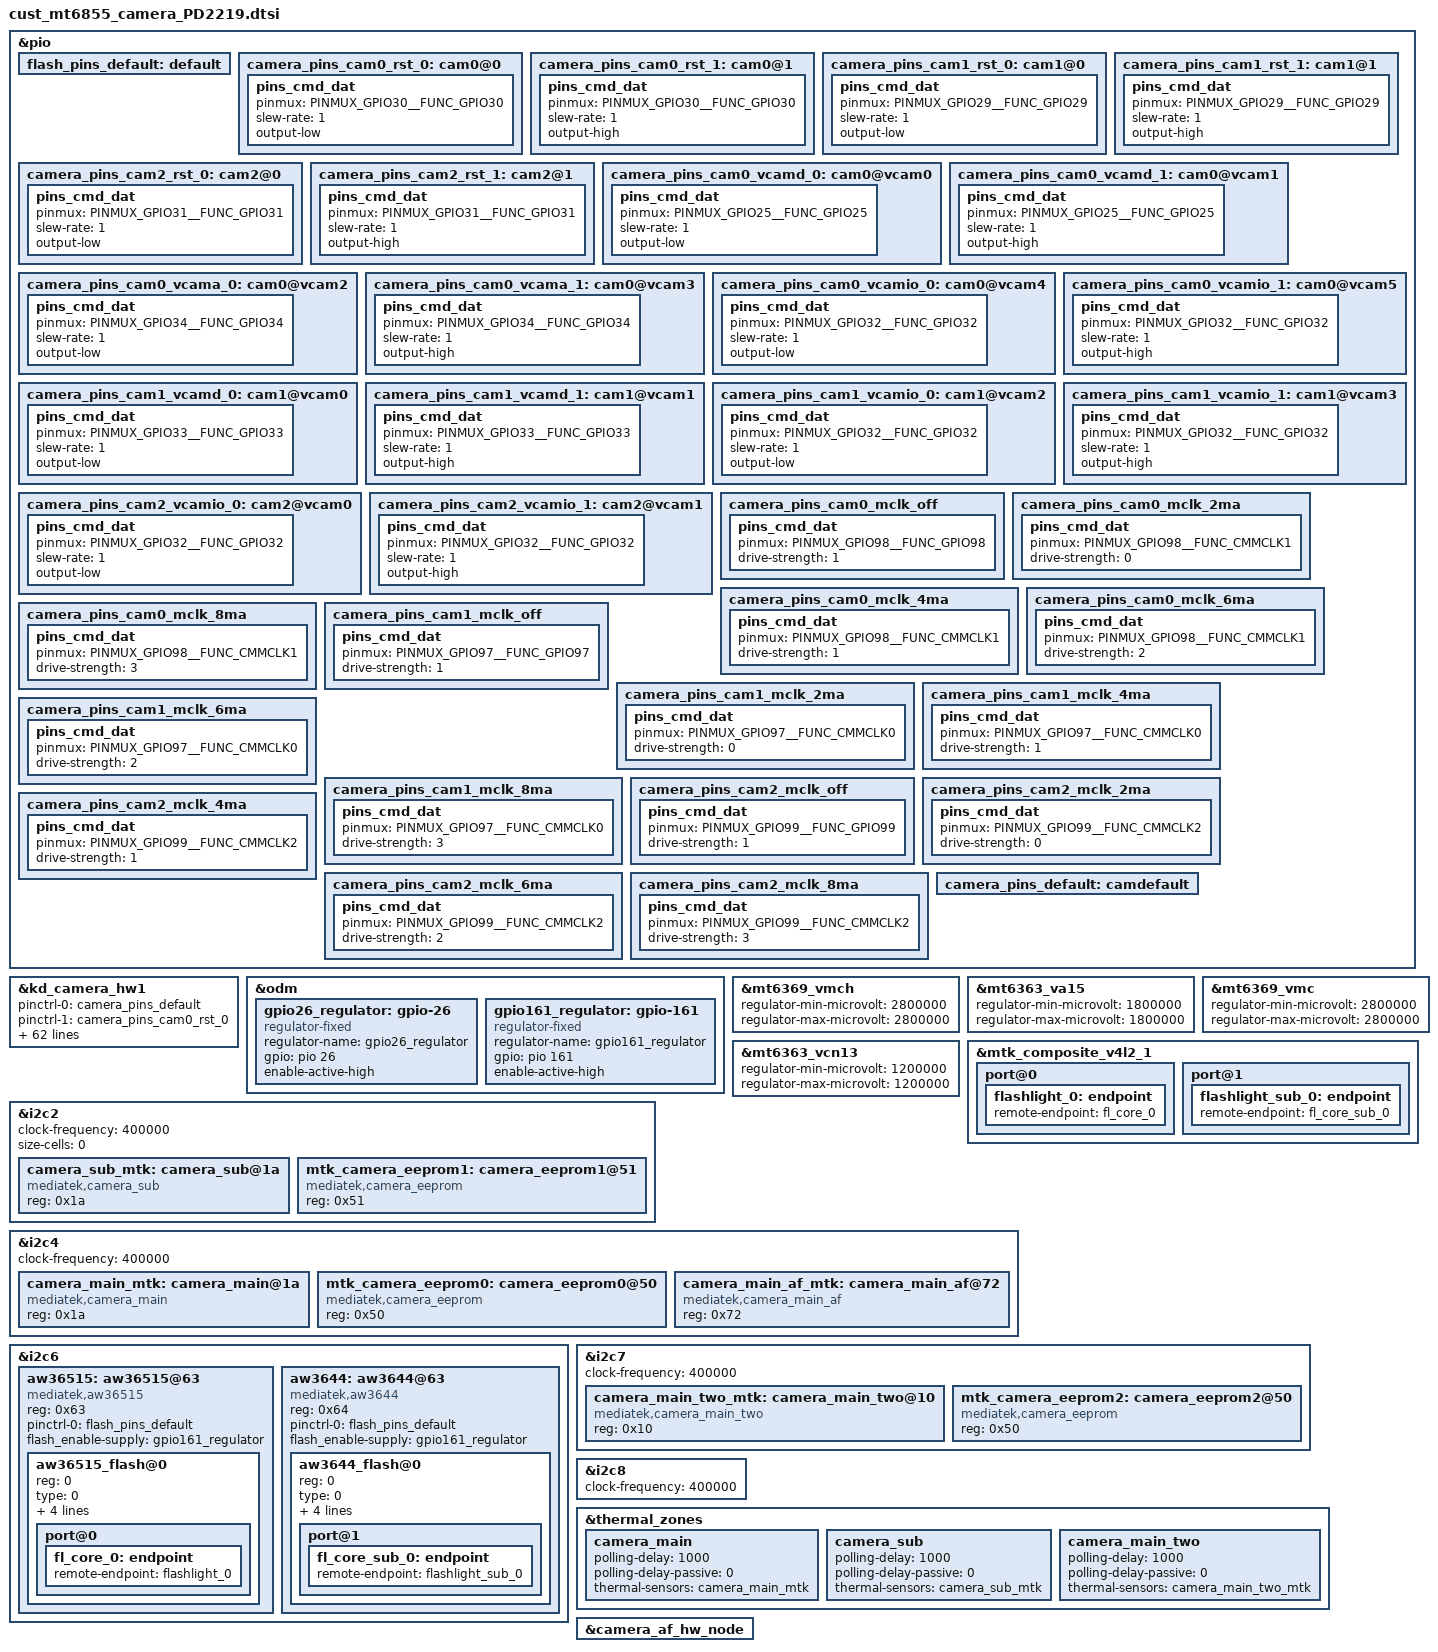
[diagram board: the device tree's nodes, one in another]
// SPDX-License-Identifier: GPL-2.0
/* Copyright (c) 2020 MediaTek Inc. */
/* CAMERA GPIO standardization */

/* flash led */
&pio {
	flash_pins_default: default {
	};
};
&pio {
	camera_pins_cam0_rst_0: cam0@0 {
		pins_cmd_dat {
			pinmux = <PINMUX_GPIO30__FUNC_GPIO30>;
			slew-rate = <1>;
			output-low;
		};
	};
	camera_pins_cam0_rst_1: cam0@1 {
		pins_cmd_dat {
			pinmux = <PINMUX_GPIO30__FUNC_GPIO30>;
			slew-rate = <1>;
			output-high;
		};
	};

	camera_pins_cam1_rst_0: cam1@0 {
		pins_cmd_dat {
			pinmux = <PINMUX_GPIO29__FUNC_GPIO29>;
			slew-rate = <1>;
			output-low;
		};
	};
	camera_pins_cam1_rst_1: cam1@1 {
		pins_cmd_dat {
			pinmux = <PINMUX_GPIO29__FUNC_GPIO29>;
			slew-rate = <1>;
			output-high;
		};
	};

	camera_pins_cam2_rst_0: cam2@0 {
		pins_cmd_dat {
			pinmux = <PINMUX_GPIO31__FUNC_GPIO31>;
			slew-rate = <1>;
			output-low;
		};
	};
	camera_pins_cam2_rst_1: cam2@1 {
		pins_cmd_dat {
			pinmux = <PINMUX_GPIO31__FUNC_GPIO31>;
			slew-rate = <1>;
			output-high;
		};
	};

	camera_pins_cam0_vcamd_0: cam0@vcam0 {
		pins_cmd_dat {
			pinmux = <PINMUX_GPIO25__FUNC_GPIO25>;
			slew-rate = <1>;
			output-low;
		};
	};
	camera_pins_cam0_vcamd_1: cam0@vcam1 {
		pins_cmd_dat {
			pinmux = <PINMUX_GPIO25__FUNC_GPIO25>;
			slew-rate = <1>;
			output-high;
		};
	};
	camera_pins_cam0_vcama_0: cam0@vcam2 {
		pins_cmd_dat {
			pinmux = <PINMUX_GPIO34__FUNC_GPIO34>;
			slew-rate = <1>;
			output-low;
		};
	};
	camera_pins_cam0_vcama_1: cam0@vcam3 {
		pins_cmd_dat {
			pinmux = <PINMUX_GPIO34__FUNC_GPIO34>;
			slew-rate = <1>;
			output-high;
		};
	};
	camera_pins_cam0_vcamio_0: cam0@vcam4 {
		pins_cmd_dat {
			pinmux = <PINMUX_GPIO32__FUNC_GPIO32>;
			slew-rate = <1>;
			output-low;
		};
	};
	camera_pins_cam0_vcamio_1: cam0@vcam5 {
		pins_cmd_dat {
			pinmux = <PINMUX_GPIO32__FUNC_GPIO32>;
			slew-rate = <1>;
			output-high;
		};
	};
	camera_pins_cam1_vcamd_0: cam1@vcam0 {
		pins_cmd_dat {
			pinmux = <PINMUX_GPIO33__FUNC_GPIO33>;
			slew-rate = <1>;
			output-low;
		};
	};
	camera_pins_cam1_vcamd_1: cam1@vcam1 {
		pins_cmd_dat {
			pinmux = <PINMUX_GPIO33__FUNC_GPIO33>;
			slew-rate = <1>;
			output-high;
		};
	};
	camera_pins_cam1_vcamio_0: cam1@vcam2 {
		pins_cmd_dat {
			pinmux = <PINMUX_GPIO32__FUNC_GPIO32>;
			slew-rate = <1>;
			output-low;
		};
	};
	camera_pins_cam1_vcamio_1: cam1@vcam3 {
		pins_cmd_dat {
			pinmux = <PINMUX_GPIO32__FUNC_GPIO32>;
			slew-rate = <1>;
			output-high;
		};
	};
	camera_pins_cam2_vcamio_0: cam2@vcam0 {
		pins_cmd_dat {
			pinmux = <PINMUX_GPIO32__FUNC_GPIO32>;
			slew-rate = <1>;
			output-low;
		};
	};
	camera_pins_cam2_vcamio_1: cam2@vcam1 {
		pins_cmd_dat {
			pinmux = <PINMUX_GPIO32__FUNC_GPIO32>;
			slew-rate = <1>;
			output-high;
		};
	};
	camera_pins_cam0_mclk_off: camera_pins_cam0_mclk_off {
		pins_cmd_dat {
			pinmux = <PINMUX_GPIO98__FUNC_GPIO98>;
			drive-strength = <1>;
		};
	};
	camera_pins_cam0_mclk_2ma: camera_pins_cam0_mclk_2ma {
		pins_cmd_dat {
			pinmux = <PINMUX_GPIO98__FUNC_CMMCLK1>;
			drive-strength = <0>;
		};
	};
	camera_pins_cam0_mclk_4ma: camera_pins_cam0_mclk_4ma {
		pins_cmd_dat {
			pinmux = <PINMUX_GPIO98__FUNC_CMMCLK1>;
			drive-strength = <1>;
		};
	};
	camera_pins_cam0_mclk_6ma: camera_pins_cam0_mclk_6ma {
		pins_cmd_dat {
			pinmux = <PINMUX_GPIO98__FUNC_CMMCLK1>;
			drive-strength = <2>;
		};
	};
	camera_pins_cam0_mclk_8ma: camera_pins_cam0_mclk_8ma {
		pins_cmd_dat {
			pinmux = <PINMUX_GPIO98__FUNC_CMMCLK1>;
			drive-strength = <3>;
		};
	};
	camera_pins_cam1_mclk_off: camera_pins_cam1_mclk_off {
		pins_cmd_dat {
			pinmux = <PINMUX_GPIO97__FUNC_GPIO97>;
			drive-strength = <1>;
		};
	};
	camera_pins_cam1_mclk_2ma: camera_pins_cam1_mclk_2ma {
		pins_cmd_dat {
			pinmux = <PINMUX_GPIO97__FUNC_CMMCLK0>;
			drive-strength = <0>;
		};
	};
	camera_pins_cam1_mclk_4ma: camera_pins_cam1_mclk_4ma {
		pins_cmd_dat {
			pinmux = <PINMUX_GPIO97__FUNC_CMMCLK0>;
			drive-strength = <1>;
		};
	};
	camera_pins_cam1_mclk_6ma: camera_pins_cam1_mclk_6ma {
		pins_cmd_dat {
			pinmux = <PINMUX_GPIO97__FUNC_CMMCLK0>;
			drive-strength = <2>;
		};
	};
	camera_pins_cam1_mclk_8ma: camera_pins_cam1_mclk_8ma {
		pins_cmd_dat {
			pinmux = <PINMUX_GPIO97__FUNC_CMMCLK0>;
			drive-strength = <3>;
		};
	};
	camera_pins_cam2_mclk_off: camera_pins_cam2_mclk_off {
		pins_cmd_dat {
			pinmux = <PINMUX_GPIO99__FUNC_GPIO99>;
			drive-strength = <1>;
		};
	};
	camera_pins_cam2_mclk_2ma: camera_pins_cam2_mclk_2ma {
		pins_cmd_dat {
			pinmux = <PINMUX_GPIO99__FUNC_CMMCLK2>;
			drive-strength = <0>;
		};
	};
	camera_pins_cam2_mclk_4ma: camera_pins_cam2_mclk_4ma {
		pins_cmd_dat {
			pinmux = <PINMUX_GPIO99__FUNC_CMMCLK2>;
			drive-strength = <1>;
		};
	};
	camera_pins_cam2_mclk_6ma: camera_pins_cam2_mclk_6ma {
		pins_cmd_dat {
			pinmux = <PINMUX_GPIO99__FUNC_CMMCLK2>;
			drive-strength = <2>;
		};
	};
	camera_pins_cam2_mclk_8ma: camera_pins_cam2_mclk_8ma {
		pins_cmd_dat {
			pinmux = <PINMUX_GPIO99__FUNC_CMMCLK2>;
			drive-strength = <3>;
		};
	};
	camera_pins_default: camdefault {
	};
};
&kd_camera_hw1 {
	pinctrl-names = "default",
			"cam0_rst0", "cam0_rst1",
			"cam1_rst0", "cam1_rst1",
			"cam2_rst0", "cam2_rst1",
			"cam0_ldo_vcamd_0", "cam0_ldo_vcamd_1",
			"cam0_ldo_vcama_0", "cam0_ldo_vcama_1",
			"cam0_ldo_vcamio_0", "cam0_ldo_vcamio_1",
			"cam1_ldo_vcamd_0", "cam1_ldo_vcamd_1",
			"cam1_ldo_vcamio_0", "cam1_ldo_vcamio_1",
			"cam2_ldo_vcamio_0", "cam2_ldo_vcamio_1",
			"cam0_mclk_off",
			"cam0_mclk_2mA", "cam0_mclk_4mA",
			"cam0_mclk_6mA", "cam0_mclk_8mA",
			"cam1_mclk_off",
			"cam1_mclk_2mA", "cam1_mclk_4mA",
			"cam1_mclk_6mA", "cam1_mclk_8mA",
			"cam2_mclk_off",
			"cam2_mclk_2mA", "cam2_mclk_4mA",
			"cam2_mclk_6mA", "cam2_mclk_8mA";
	pinctrl-0 = <&camera_pins_default>;
	pinctrl-1 = <&camera_pins_cam0_rst_0>;
	pinctrl-2 = <&camera_pins_cam0_rst_1>;
	pinctrl-3 = <&camera_pins_cam1_rst_0>;
	pinctrl-4 = <&camera_pins_cam1_rst_1>;
	pinctrl-5 = <&camera_pins_cam2_rst_0>;
	pinctrl-6 = <&camera_pins_cam2_rst_1>;
	pinctrl-7 = <&camera_pins_cam0_vcamd_0>;
	pinctrl-8 = <&camera_pins_cam0_vcamd_1>;
	pinctrl-9 = <&camera_pins_cam0_vcama_0>;
	pinctrl-10 = <&camera_pins_cam0_vcama_1>;
	pinctrl-11 = <&camera_pins_cam0_vcamio_0>;
	pinctrl-12 = <&camera_pins_cam0_vcamio_1>;
	pinctrl-13 = <&camera_pins_cam1_vcamd_0>;
	pinctrl-14 = <&camera_pins_cam1_vcamd_1>;
	pinctrl-15 = <&camera_pins_cam1_vcamio_0>;
	pinctrl-16 = <&camera_pins_cam1_vcamio_1>;
	pinctrl-17 = <&camera_pins_cam2_vcamio_0>;
	pinctrl-18 = <&camera_pins_cam2_vcamio_1>;
	pinctrl-19 = <&camera_pins_cam0_mclk_off>;
	pinctrl-20 = <&camera_pins_cam0_mclk_2ma>;
	pinctrl-21 = <&camera_pins_cam0_mclk_4ma>;
	pinctrl-22 = <&camera_pins_cam0_mclk_6ma>;
	pinctrl-23 = <&camera_pins_cam0_mclk_8ma>;
	pinctrl-24 = <&camera_pins_cam1_mclk_off>;
	pinctrl-25 = <&camera_pins_cam1_mclk_2ma>;
	pinctrl-26 = <&camera_pins_cam1_mclk_4ma>;
	pinctrl-27 = <&camera_pins_cam1_mclk_6ma>;
	pinctrl-28 = <&camera_pins_cam1_mclk_8ma>;
	pinctrl-29 = <&camera_pins_cam2_mclk_off>;
	pinctrl-30 = <&camera_pins_cam2_mclk_2ma>;
	pinctrl-31 = <&camera_pins_cam2_mclk_4ma>;
	pinctrl-32 = <&camera_pins_cam2_mclk_6ma>;
	pinctrl-33 = <&camera_pins_cam2_mclk_8ma>;

	/* main */
	cam0_vcamio-supply = <&mt6363_va15>;
	cam0_vcamaf_def-supply = <&mt6369_vmch>;

	/* front */
	cam1_vcama-supply = <&gpio26_regulator>;
	cam1_vcama1-supply = <&mt6369_vmc>;
	cam1_vcamd-supply = <&mt6363_vcn13>;
	cam1_vcamio-supply = <&mt6363_va15>;

	/* main2 (macro) */
	cam2_vcama-supply = <&gpio26_regulator>;
	cam2_vcama1-supply = <&mt6369_vmc>;
	cam2_vcamio-supply = <&mt6363_va15>;

	cam0_enable_sensor = "s5kjn1sq03pd2219_mipi_raw";
	cam1_enable_sensor = "s5k4h7pd2219_mipi_raw";
	cam2_enable_sensor = "ov02b10pd2219_mipi_raw ov02b10v1pd2219_mipi_raw";

	cam0_pin_mclk = "mclk";
	cam0_pin_rst = "gpio";
	cam0_pin_vcama = "gpio";
	cam0_pin_vcamd = "gpio";
	cam0_pin_vcamio = "regulator";
	cam0_pin_vcamaf_def = "regulator";
	cam1_pin_mclk = "mclk";
	cam1_pin_rst = "gpio";
	cam1_pin_vcama = "regulator";
	cam1_pin_vcama1 = "regulator";
	cam1_pin_vcamd = "regulator";
	cam1_pin_vcamio = "regulator";
	cam2_pin_mclk = "mclk";
	cam2_pin_rst = "gpio";
	cam2_pin_vcama = "regulator";
	cam2_pin_vcama1 = "regulator";
	cam2_pin_vcamio = "regulator";

	status = "okay";
};
&odm {
	gpio26_regulator:gpio-26 {
		compatible = "regulator-fixed";
		regulator-name = "gpio26_regulator";
		gpio = <&pio 26 0x0>;
		enable-active-high;
		status = "okay";
	};
	gpio161_regulator:gpio-161 {
		compatible = "regulator-fixed";
		regulator-name = "gpio161_regulator";
		gpio = <&pio 161 0x0>;
		enable-active-high;
		status = "okay";
	};
};
/* CAMERA GPIO end */
&mt6369_vmch{
	regulator-min-microvolt = <2800000>;
	regulator-max-microvolt = <2800000>;
};

&mt6363_va15{
	regulator-min-microvolt = <1800000>;
	regulator-max-microvolt = <1800000>;
};

&mt6369_vmc{
	regulator-min-microvolt = <2800000>;
	regulator-max-microvolt = <2800000>;
};

&mt6363_vcn13{
	regulator-min-microvolt = <1200000>;
	regulator-max-microvolt = <1200000>;
};

&mtk_composite_v4l2_1 {
	port@0 {
		flashlight_0: endpoint {
			remote-endpoint = <&fl_core_0>;
		};
	};
	port@1 {
		flashlight_sub_0: endpoint {
			remote-endpoint = <&fl_core_sub_0>;
		};
	};
};
/* CAMERA EEPROM */
&i2c2 {
	status = "okay";
	clock-frequency = <400000>;
	#address-cells = <1>;
	size-cells = <0>;
	camera_sub_mtk:camera_sub@1a {
		compatible = "mediatek,camera_sub";
		#thermal-sensor-cells = <0>;
		reg = <0x1a>;
		status = "okay";
	};
	mtk_camera_eeprom1:camera_eeprom1@51 {
		compatible = "mediatek,camera_eeprom";
		reg = <0x51>;
		status = "okay";
	};
};
&i2c4 {
	status = "okay";
	clock-frequency = <400000>;
	#address-cells = <1>;
	#size-cells = <0>;
	camera_main_mtk:camera_main@1a {
		compatible = "mediatek,camera_main";
		#thermal-sensor-cells = <0>;
		reg = <0x1a>;
		status = "okay";
	};
	mtk_camera_eeprom0:camera_eeprom0@50 {
		compatible = "mediatek,camera_eeprom";
		reg = <0x50>;
		status = "okay";
	};
	camera_main_af_mtk:camera_main_af@72 {
		compatible = "mediatek,camera_main_af";
		reg = <0x72>;
		status = "okay";
	};
};
&i2c6 {
	aw36515:aw36515@63 {
		compatible = "mediatek,aw36515";
		reg = <0x63>;
		#cooling-cells = <2>;
		pinctrl-names = "default";
		pinctrl-0 = <&flash_pins_default>;
		flash_enable-supply = <&gpio161_regulator>;
		status = "okay";
		aw36515_flash@0{
			reg = <0>;
			type = <0>;
			ct = <0>;
			part = <0>;
			factory_torch_brt = <100>;  //LED0:100mA, add for factory torch test:AT+BKSG=1
			factory_flash_brt = <1050>; //LED0:1050mA, add for factory flash test:AT+FLAMP=1,1
			port@0 {
				fl_core_0: endpoint {
					remote-endpoint = <&flashlight_0>;
				};
			};
		};
	};
	aw3644:aw3644@63 {
		compatible = "mediatek,aw3644";
		reg = <0x64>;
		#cooling-cells = <2>;
		pinctrl-names = "default";
		pinctrl-0 = <&flash_pins_default>;
		flash_enable-supply = <&gpio161_regulator>;
		status = "okay";
		aw3644_flash@0{
			reg = <0>;
			type = <0>;
			ct = <0>;
			part = <0>;
			factory_torch_brt = <100>;  //LED0:100mA, add for factory torch test:AT+BKSG=1
			factory_flash_brt = <1050>; //LED0:1050mA, add for factory flash test:AT+FLAMP=1,1
			port@1 {
				fl_core_sub_0: endpoint {
					remote-endpoint = <&flashlight_sub_0>;
				};
			};
		};
	};
};
&i2c7 {
	status = "okay";
	clock-frequency = <400000>;
	#address-cells = <1>;
	#size-cells = <0>;

	camera_main_two_mtk:camera_main_two@10 {
		compatible = "mediatek,camera_main_two";
		#thermal-sensor-cells = <0>;
		reg = <0x10>;
		status = "okay";
	};
	mtk_camera_eeprom2:camera_eeprom2@50 {
		compatible = "mediatek,camera_eeprom";
		reg = <0x50>;
		status = "okay";
	};
};
&i2c8 {
	status = "okay";
	clock-frequency = <400000>;
	#address-cells = <1>;
	#size-cells = <0>;

};
/* CAMERA EEPROM end */


/* CAMERA TZ config */
&thermal_zones {
	camera_main: camera_main {
		polling-delay = <1000>; /* milliseconds */
		polling-delay-passive = <0>; /* milliseconds */
		thermal-sensors = <&camera_main_mtk>;
	};
	camera_sub: camera_sub {
		polling-delay = <1000>; /* milliseconds */
		polling-delay-passive = <0>; /* milliseconds */
		thermal-sensors = <&camera_sub_mtk>;
	};
	camera_main_two: camera_main_two {
		polling-delay = <1000>; /* milliseconds */
		polling-delay-passive = <0>; /* milliseconds */
		thermal-sensors = <&camera_main_two_mtk>;
	};
};
/* CAMERA TZ config end */
/* camera af start */
&camera_af_hw_node {
	//camaf_m1_pmic-supply = <&mt6369_vmch>;
	status = "okay";
};
/* camera af end */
